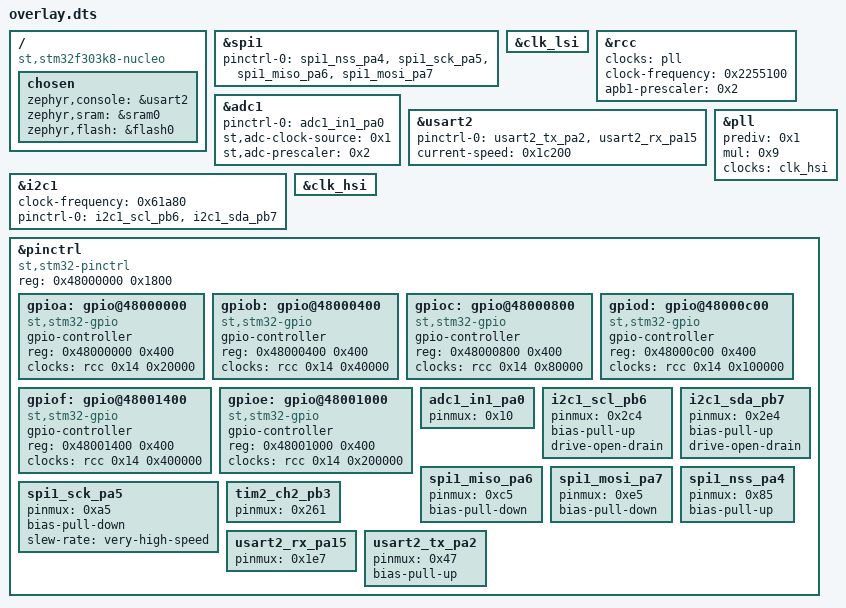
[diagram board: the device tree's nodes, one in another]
/ {
	compatible = "st,stm32f303k8-nucleo";
	chosen {
		zephyr,console = &usart2;
		zephyr,sram = &sram0;
		zephyr,flash = &flash0;
	};
};
&spi1{
	status = "okay";
	pinctrl-0 = < &spi1_nss_pa4 &spi1_sck_pa5 &spi1_miso_pa6 &spi1_mosi_pa7 >;
	pinctrl-names = "default";
};
&clk_lsi{
	status = "okay";
};
&rcc{
	clocks = < &pll >;
	clock-frequency = < 0x2255100 >;
	apb1-prescaler = < 0x2 >;
};
&adc1{
	status = "okay";
	pinctrl-0 = < &adc1_in1_pa0 >;
	pinctrl-names = "default";
	st,adc-clock-source = < 0x1 >;
	st,adc-prescaler = < 0x2 >;
};
&usart2{
	status = "okay";
	pinctrl-0 = < &usart2_tx_pa2 &usart2_rx_pa15 >;
	pinctrl-names = "default";
	current-speed = < 0x1c200 >;
};
&pll{
	status = "okay";
	prediv = < 0x1 >;
	mul = < 0x9 >;
	clocks = < &clk_hsi >;
};
&i2c1{
	clock-frequency = < 0x61a80 >;
	status = "okay";
	pinctrl-0 = < &i2c1_scl_pb6 &i2c1_sda_pb7 >;
	pinctrl-names = "default";
};
&clk_hsi{
	status = "okay";
};
&pinctrl{
	compatible = "st,stm32-pinctrl";
	#address-cells = < 0x1 >;
	#size-cells = < 0x1 >;
	reg = < 0x48000000 0x1800 >;
	gpioa: gpio@48000000 {
		compatible = "st,stm32-gpio";
		gpio-controller;
		#gpio-cells = < 0x2 >;
		reg = < 0x48000000 0x400 >;
		clocks = < &rcc 0x14 0x20000 >;
	};
	gpiob: gpio@48000400 {
		compatible = "st,stm32-gpio";
		gpio-controller;
		#gpio-cells = < 0x2 >;
		reg = < 0x48000400 0x400 >;
		clocks = < &rcc 0x14 0x40000 >;
	};
	gpioc: gpio@48000800 {
		compatible = "st,stm32-gpio";
		gpio-controller;
		#gpio-cells = < 0x2 >;
		reg = < 0x48000800 0x400 >;
		clocks = < &rcc 0x14 0x80000 >;
	};
	gpiod: gpio@48000c00 {
		compatible = "st,stm32-gpio";
		gpio-controller;
		#gpio-cells = < 0x2 >;
		reg = < 0x48000c00 0x400 >;
		clocks = < &rcc 0x14 0x100000 >;
	};
	gpiof: gpio@48001400 {
		compatible = "st,stm32-gpio";
		gpio-controller;
		#gpio-cells = < 0x2 >;
		reg = < 0x48001400 0x400 >;
		clocks = < &rcc 0x14 0x400000 >;
	};
	gpioe: gpio@48001000 {
		compatible = "st,stm32-gpio";
		gpio-controller;
		#gpio-cells = < 0x2 >;
		reg = < 0x48001000 0x400 >;
		clocks = < &rcc 0x14 0x200000 >;
	};
	adc1_in1_pa0: adc1_in1_pa0 {
		pinmux = < 0x10 >;
	};
	i2c1_scl_pb6: i2c1_scl_pb6 {
		pinmux = < 0x2c4 >;
		bias-pull-up;
		drive-open-drain;
	};
	i2c1_sda_pb7: i2c1_sda_pb7 {
		pinmux = < 0x2e4 >;
		bias-pull-up;
		drive-open-drain;
	};
	spi1_miso_pa6: spi1_miso_pa6 {
		pinmux = < 0xc5 >;
		bias-pull-down;
	};
	spi1_mosi_pa7: spi1_mosi_pa7 {
		pinmux = < 0xe5 >;
		bias-pull-down;
	};
	spi1_nss_pa4: spi1_nss_pa4 {
		pinmux = < 0x85 >;
		bias-pull-up;
	};
	spi1_sck_pa5: spi1_sck_pa5 {
		pinmux = < 0xa5 >;
		bias-pull-down;
		slew-rate = "very-high-speed";
	};
	tim2_ch2_pb3: tim2_ch2_pb3 {
		pinmux = < 0x261 >;
	};
	usart2_rx_pa15: usart2_rx_pa15 {
		pinmux = < 0x1e7 >;
	};
	usart2_tx_pa2: usart2_tx_pa2 {
		pinmux = < 0x47 >;
		bias-pull-up;
	};
};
